# ELM register map
Vendor: Texas Instruments
Peripheral module from a debugger description file (folder am437x).
Registers are 32-bit, access not given, no defined reset value unless marked. A register's access mark holds for its fields unless they carry their own. Offsets are as the file gives them; lines under a group give offsets from that group; [hi:lo] are bit positions; {n}, {i} and the like mark numbered series; 'fields as' and 'values as' point back to an identical list; <NAME> marks a mode.

## ELM
0x00 ELM_REVISION ro — This register contains the IP revision code.
  [31:0] REVISION — IP Revision, value 0 to FFFF FFFFh.
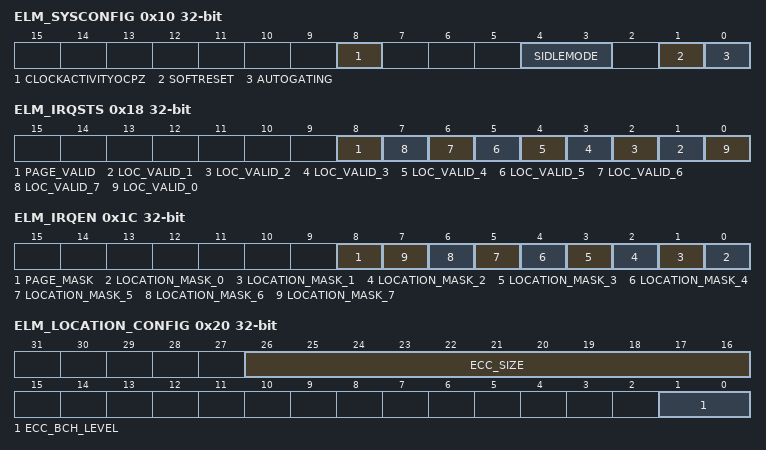
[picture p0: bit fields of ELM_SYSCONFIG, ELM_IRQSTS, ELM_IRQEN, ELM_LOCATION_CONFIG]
0x10 ELM_SYSCONFIG access per field — This register allows controlling various parameters of the OCP interface.
  [8] CLOCKACTIVITYOCPZ rw — OCP Clock activity when module is in IDLE mode (during wake up mode period).
    1=en_2_0x1 (OCP Clock is maintained during wake up period); 0=en_1_0x0 (OCP Clock can be switch-off)
  [4:3] SIDLEMODE rw — Slave interface power management (IDLE req/ack control).
    3=en_4_0x3 (Reserved - do not use); 2=en_3_0x2 (SMART Idle. The acknowledgment to an IDLE request is given based on the internal activity.); 1=en_2_0x1 (NO idle. IDLE request is never acknowledged.); 0=en_1_0x0 (FORCE Idle. IDLE request is acknowledged unconditionally and immediately. (Default Dumb mode for safety))
  [1] SOFTRESET rw — Module software reset. [[br]]This bit is automatically reset by hardware (During reads, it always returns 0.). [[br]]It has same effect as the OCP hardware reset.
    1=en_2_0x1 (Start soft reset sequence.); 0=en_1_0x0 (Normal mode.)
  [0] AUTOGATING rw — Internal OCP clock gating strategy. [[br]](No module visible impact other than saving power.)
    1=en_2_0x1 (Automatic internal OCP clock gating strategy is applied based on the OCP interface activity.); 0=en_1_0x0 (OCP clock is free-running.)
0x14 ELM_SYSSTS ro
  [0] RESETDONE — Internal reset monitoring (OCP domain). [[br]]Undefined since: From hardware perspective, the reset state is 0. [[br]]From software user perspective, when the accessible module is 1.
    1=en_2_0x1 (Reset is done (completed)); 0=en_1_0x0 (Reset is on-going)
0x18 ELM_IRQSTS access per field — This register doubles as a status register for the error-location processes.
  [8] PAGE_VALID rw — Error-location status for a full page, based on the mask definition.
    1=en_2_0x1 (Read: All error locations valid.); 0=en_1_0x0 (Write: No effect.)
  [n] LOC_VALID_{n} rw (n=1..7) — Error-location status for syndrome polynomial {n}.
    1=en_2_0x1 (Read: Error-location process completed.); 0=en_1_0x0 (Write: No effect.)
  [0] LOC_VALID_0 rw — Error-location status for syndrome polynomial 0.
    1=en_2_0x1 (Clear interrupt.); 0=en_1_0x0 (No syndrome processed or process in progress.)
0x1C ELM_IRQEN access per field
  [all] fields
    1=en_2_0x1 (Enable interrupt.); 0=en_1_0x0 (Disable interrupt.)
  [8] PAGE_MASK rw — Page interrupt mask bit
  [n] LOCATION_MASK_{n} rw (n=0..7) — Error-location interrupt mask bit for syndrome polynomial {n}.
0x20 ELM_LOCATION_CONFIG access per field
  [26:16] ECC_SIZE rw — Maximum size of the buffers for which the error-location engine is used, in number of nibbles (4 bits entities), value 0 to 7FFh.
  [1:0] ECC_BCH_LEVEL rw — Error correction level.
    3=en_4_0x3 (Reserved.); 2=en_3_0x2 (16 bits.); 1=en_2_0x1 (8 bits.); 0=en_1_0x0 (4 bits.)
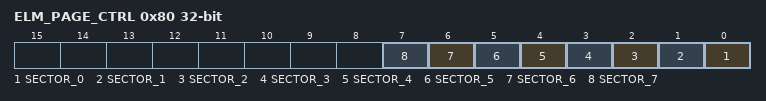
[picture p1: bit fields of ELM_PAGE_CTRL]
0x80 ELM_PAGE_CTRL access per field
  [n] SECTOR_{n} rw (n=0..7) — Set to 1 if syndrome polynomial {n} is part of the page in page mode. [[br]]Must be 0 in continuous mode.
{0x400+0x40*i} ELM_SYNDROME_FRAGMENT_0_{i} (i=0..7)
{0x404+0x40*i} ELM_SYNDROME_FRAGMENT_1_{i} (i=0..7)
{0x408+0x40*i} ELM_SYNDROME_FRAGMENT_2_{i} (i=0..7)
{0x40C+0x40*i} ELM_SYNDROME_FRAGMENT_3_{i} (i=0..7)
{0x410+0x40*i} ELM_SYNDROME_FRAGMENT_4_{i} (i=0..7)
{0x414+0x40*i} ELM_SYNDROME_FRAGMENT_5_{i} (i=0..7)
{0x418+0x40*i} ELM_SYNDROME_FRAGMENT_6_{i} (i=0..7)
{0x800+0x100*i} ELM_LOCATION_STS_{i} (i=0..7)
{0x880+4i} ELM_ERROR_LOCATION_{i}_0 (i=0..15)
{0x980+4i} ELM_ERROR_LOCATION_{i}_1 (i=0..15)
{0xA80+4i} ELM_ERROR_LOCATION_{i}_2 (i=0..15)
{0xB80+4i} ELM_ERROR_LOCATION_{i}_3 (i=0..15)
{0xC80+4i} ELM_ERROR_LOCATION_{i}_4 (i=0..15)
{0xD80+4i} ELM_ERROR_LOCATION_{i}_5 (i=0..15)
{0xE80+4i} ELM_ERROR_LOCATION_{i}_6 (i=0..15)
{0xF80+4i} ELM_ERROR_LOCATION_{i}_7 (i=0..15)
